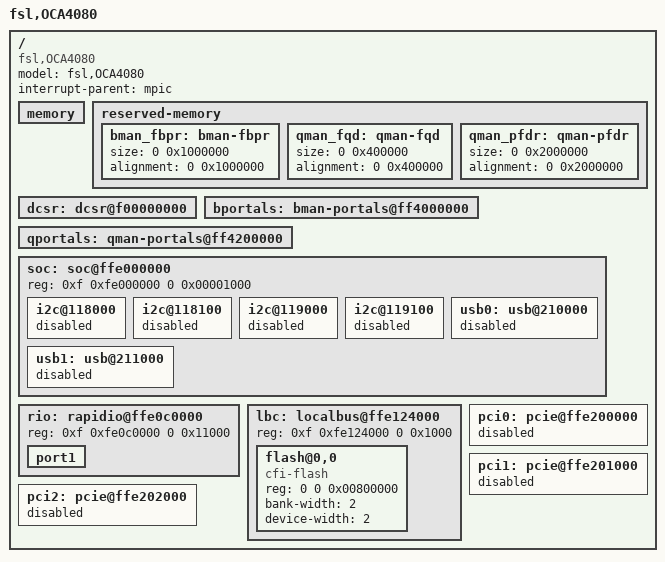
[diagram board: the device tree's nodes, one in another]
/include/ "p4080si-pre.dtsi"
/ {
	model = "fsl,OCA4080";
	compatible = "fsl,OCA4080";
	#address-cells = <2>;
	#size-cells = <2>;
	interrupt-parent = <&mpic>;
	memory {
		device_type = "memory";
	};
	reserved-memory {
		#address-cells = <2>;
		#size-cells = <2>;
		ranges;
		bman_fbpr: bman-fbpr {
			size = <0 0x1000000>;
			alignment = <0 0x1000000>;
		};
		qman_fqd: qman-fqd {
			size = <0 0x400000>;
			alignment = <0 0x400000>;
		};
		qman_pfdr: qman-pfdr {
			size = <0 0x2000000>;
			alignment = <0 0x2000000>;
		};
	};
	dcsr: dcsr@f00000000 {
		ranges = <0x00000000 0xf 0x00000000 0x01008000>;
	};
	bportals: bman-portals@ff4000000 {
		ranges = <0x0 0xf 0xf4000000 0x200000>;
	};
	qportals: qman-portals@ff4200000 {
		ranges = <0x0 0xf 0xf4200000 0x200000>;
	};
	soc: soc@ffe000000 {
		ranges = <0x00000000 0xf 0xfe000000 0x1000000>;
		reg = <0xf 0xfe000000 0 0x00001000>;
		i2c@118000 {
			status = "disabled";
		};
		i2c@118100 {
			status = "disabled";
		};
		i2c@119000 {
			status = "disabled";
		};
		i2c@119100 {
			status = "disabled";
		};
		usb0: usb@210000 {
			status = "disabled";
		};
		usb1: usb@211000 {
			status = "disabled";
		};
	};
	rio: rapidio@ffe0c0000 {
		reg = <0xf 0xfe0c0000 0 0x11000>;
		port1 {
			ranges = <0 0 0xc 0x20000000 0 0x10000000>;
		};
	};
	lbc: localbus@ffe124000 {
		reg = <0xf 0xfe124000 0 0x1000>;
		ranges = <0 0 0xf 0xef800000 0x800000>;
		flash@0,0 {
			compatible = "cfi-flash";
			reg = <0 0 0x00800000>;
			bank-width = <2>;
			device-width = <2>;
		};
	};
	pci0: pcie@ffe200000 {
		status = "disabled";
	};
	pci1: pcie@ffe201000 {
		status = "disabled";
	};
	pci2: pcie@ffe202000 {
		status = "disabled";
	};
};
/include/ "p4080si-post.dtsi"
